AUTOSAR XML (schema 4-2-2)
package /Components
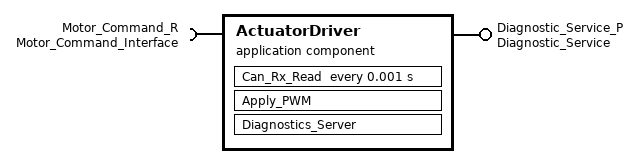
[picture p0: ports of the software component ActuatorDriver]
  application sw component type ActuatorDriver
    provide port Diagnostic_Service_P: provided-interface=Diagnostic_Service
    require port Motor_Command_R: required-interface=Motor_Command_Interface
    behavior ActuatorDriverBehavior
      data received event Cmd_Received: start-on-event=Can_Rx_Read
      timing event PWM_Update_1ms: start-on-event=Can_Rx_Read, period=0.001
      runnable Apply_PWM: minimum-start-interval=0.001, symbol=ActuatorDriver_Apply_PWM
        data-receive-point-by-arguments:
          access MotorCommandAccess: accessed-variable=Motor_Command_R.MotorCommandData
      runnable Diagnostics_Server: minimum-start-interval=0.01, symbol=ActuatorDriver_Diagnostics_Server
        sync call DiagnosticsCallPoint: called-from-within-exclusive-area=ActuatorDriverEA, operation=Diagnostic_Client_R.get_status, timeout=50
